# WBZ450 register map
Vendor: Microchip
Registers are 32-bit, read-write, reset 0x0 unless marked. A register's access mark holds for its fields unless they carry their own. Addresses are absolute, and some are shared; only a register's first bit layout is shown; [hi:lo] are bit positions; {n}, {i} and the like mark numbered series.

## DMT
0x44000E00 DMTCON
  [15] ON
0x44000E04 DMTCONCLR
0x44000E08 DMTCONSET
0x44000E0C DMTCONINV
0x44000E10 DMTPRECLR
  [15:8] STEP1
0x44000E14 DMTPRECLRCLR
0x44000E18 DMTPRECLRSET
0x44000E1C DMTPRECLRINV
0x44000E20 DMTCLR
  [7:0] STEP2
0x44000E24 DMTCLRCLR
0x44000E28 DMTCLRSET
0x44000E2C DMTCLRINV
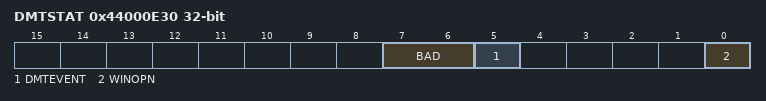
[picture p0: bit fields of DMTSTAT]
0x44000E30 DMTSTAT
  [7:6] BAD, [5] DMTEVENT, [0] WINOPN
0x44000E34 DMTSTATCLR
0x44000E38 DMTSTATSET
0x44000E3C DMTSTATINV
0x44000E40 DMTCNT
  [31:0] COUNTER
0x44000E44 DMTCNTCLR
0x44000E48 DMTCNTSET
0x44000E4C DMTCNTINV
0x44000E50 DMTHOLDREG
  [15:0] UPRCNT
0x44000E54 DMTHOLDREGCLR
0x44000E58 DMTHOLDREGSET
0x44000E5C DMTHOLDREGINV
0x44000E60 DMTPSCNT
  [31:0] PSCNT
0x44000E64 DMTPSCNTCLR
0x44000E68 DMTPSCNTSET
0x44000E6C DMTPSCNTINV
0x44000E70 DMTPSINTV
  [31:0] PSINTV
0x44000E74 DMTPSINTVCLR
0x44000E78 DMTPSINTVSET
0x44000E7C DMTPSINTVINV

## GPIOA
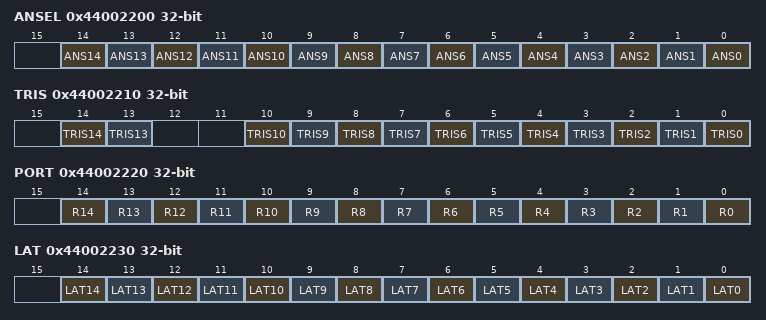
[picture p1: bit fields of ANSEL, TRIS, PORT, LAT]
0x44002200 ANSEL
  [n] ANS{n} (n=0..14)
0x44002204 ANSELCLR
0x44002208 ANSELSET
0x4400220C ANSELINV
0x44002210 TRIS
  [14] TRIS14, [13] TRIS13, [n] TRIS{n} (n=0..10)
0x44002214 TRISCLR
0x44002218 TRISSET
0x4400221C TRISINV
0x44002220 PORT
  [n] R{n} (n=0..14)
0x44002224 PORTCLR
0x44002228 PORTSET
0x4400222C PORTINV
0x44002230 LAT
  [n] LAT{n} (n=0..14)
0x44002234 LATCLR
0x44002238 LATSET
0x4400223C LATINV
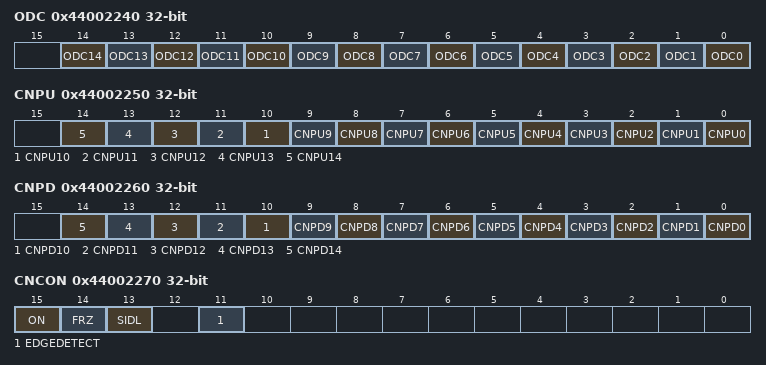
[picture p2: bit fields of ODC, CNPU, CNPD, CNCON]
0x44002240 ODC
  [n] ODC{n} (n=0..14)
0x44002244 ODCCLR
0x44002248 ODCSET
0x4400224C ODCINV
0x44002250 CNPU
  [n] CNPU{n} (n=0..14)
0x44002254 CNPUCLR
0x44002258 CNPUSET
0x4400225C CNPUINV
0x44002260 CNPD
  [n] CNPD{n} (n=0..14)
0x44002264 CNPDCLR
0x44002268 CNPDSET
0x4400226C CNPDINV
0x44002270 CNCON
  [15] ON, [14] FRZ, [13] SIDL, [11] EDGEDETECT
0x44002274 CNCONCLR
0x44002278 CNCONSET
0x4400227C CNCONINV
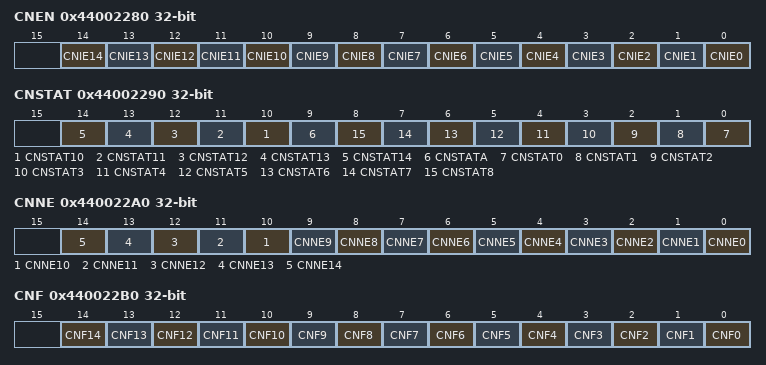
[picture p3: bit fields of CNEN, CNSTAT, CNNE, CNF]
0x44002280 CNEN
  [n] CNIE{n} (n=0..14)
0x44002284 CNENCLR
0x44002288 CNENSET
0x4400228C CNENINV
0x44002290 CNSTAT
  [n] CNSTAT{n} (n=10..14), [9] CNSTATA, [n] CNSTAT{n} (n=0..8)
0x44002294 CNSTATCLR
0x44002298 CNSTATSET
0x4400229C CNSTATINV
0x440022A0 CNNE
  [n] CNNE{n} (n=0..14)
0x440022A4 CNNECLR
0x440022A8 CNNESET
0x440022AC CNNEINV
0x440022B0 CNF
  [n] CNF{n} (n=0..14)
0x440022B4 CNFCLR
0x440022B8 CNFSET
0x440022BC CNFINV
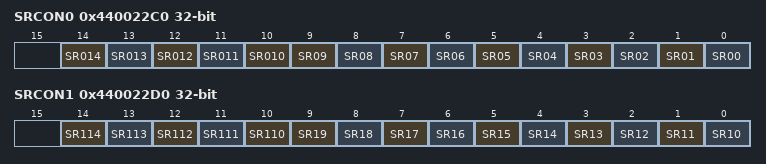
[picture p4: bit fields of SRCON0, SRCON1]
0x440022C0 SRCON0
  [n] SR{n:03} (n=10..14), [n] SR{n:02} (n=0..9)
0x440022C4 SRCON0CLR
0x440022C8 SRCON0SET
0x440022CC SRCON0INV
0x440022D0 SRCON1
  [n-100] SR{n} (n=110..114), [n-10] SR{n} (n=10..19)
0x440022D4 SRCON1CLR
0x440022D8 SRCON1SET
0x440022DC SRCON1INV

## GPIOB
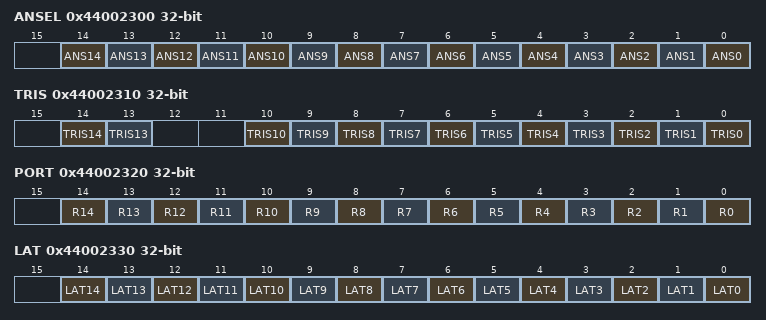
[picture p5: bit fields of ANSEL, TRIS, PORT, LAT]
0x44002300 ANSEL
  [n] ANS{n} (n=0..14)
0x44002304 ANSELCLR
0x44002308 ANSELSET
0x4400230C ANSELINV
0x44002310 TRIS
  [14] TRIS14, [13] TRIS13, [n] TRIS{n} (n=0..10)
0x44002314 TRISCLR
0x44002318 TRISSET
0x4400231C TRISINV
0x44002320 PORT
  [n] R{n} (n=0..14)
0x44002324 PORTCLR
0x44002328 PORTSET
0x4400232C PORTINV
0x44002330 LAT
  [n] LAT{n} (n=0..14)
0x44002334 LATCLR
0x44002338 LATSET
0x4400233C LATINV
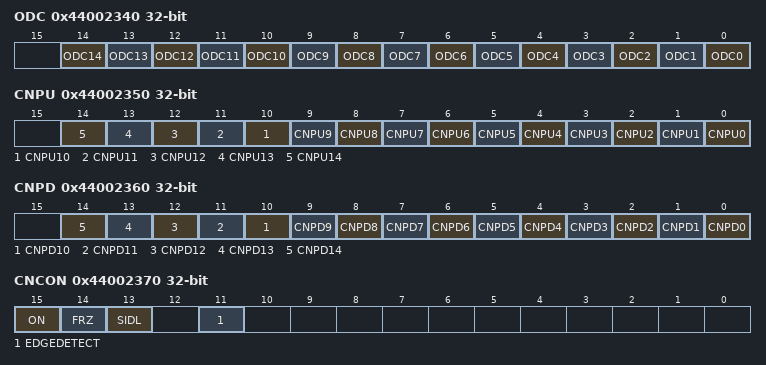
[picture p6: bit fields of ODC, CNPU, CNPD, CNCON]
0x44002340 ODC
  [n] ODC{n} (n=0..14)
0x44002344 ODCCLR
0x44002348 ODCSET
0x4400234C ODCINV
0x44002350 CNPU
  [n] CNPU{n} (n=0..14)
0x44002354 CNPUCLR
0x44002358 CNPUSET
0x4400235C CNPUINV
0x44002360 CNPD
  [n] CNPD{n} (n=0..14)
0x44002364 CNPDCLR
0x44002368 CNPDSET
0x4400236C CNPDINV
0x44002370 CNCON
  [15] ON, [14] FRZ, [13] SIDL, [11] EDGEDETECT
0x44002374 CNCONCLR
0x44002378 CNCONSET
0x4400237C CNCONINV
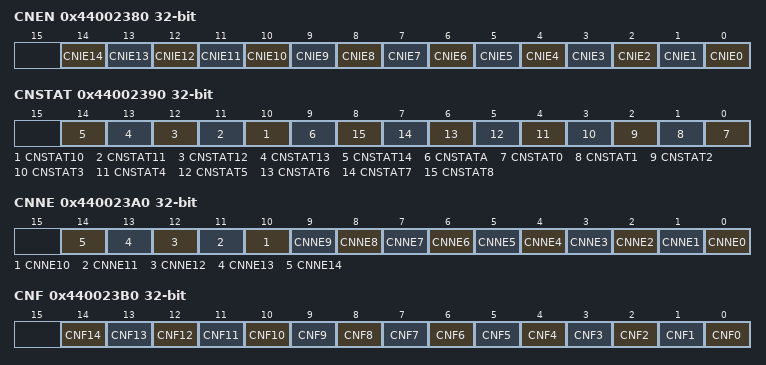
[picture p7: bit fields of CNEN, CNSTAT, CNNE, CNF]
0x44002380 CNEN
  [n] CNIE{n} (n=0..14)
0x44002384 CNENCLR
0x44002388 CNENSET
0x4400238C CNENINV
0x44002390 CNSTAT
  [n] CNSTAT{n} (n=10..14), [9] CNSTATA, [n] CNSTAT{n} (n=0..8)
0x44002394 CNSTATCLR
0x44002398 CNSTATSET
0x4400239C CNSTATINV
0x440023A0 CNNE
  [n] CNNE{n} (n=0..14)
0x440023A4 CNNECLR
0x440023A8 CNNESET
0x440023AC CNNEINV
0x440023B0 CNF
  [n] CNF{n} (n=0..14)
0x440023B4 CNFCLR
0x440023B8 CNFSET
0x440023BC CNFINV
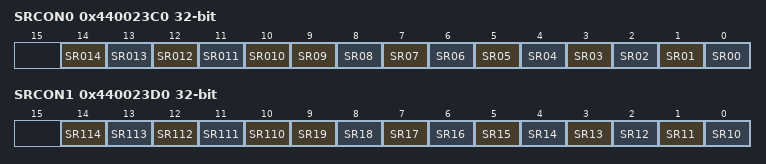
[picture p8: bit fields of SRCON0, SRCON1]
0x440023C0 SRCON0
  [n] SR{n:03} (n=10..14), [n] SR{n:02} (n=0..9)
0x440023C4 SRCON0CLR
0x440023C8 SRCON0SET
0x440023CC SRCON0INV
0x440023D0 SRCON1
  [n-100] SR{n} (n=110..114), [n-10] SR{n} (n=10..19)
0x440023D4 SRCON1CLR
0x440023D8 SRCON1SET
0x440023DC SRCON1INV
